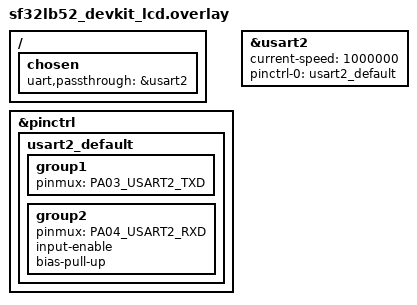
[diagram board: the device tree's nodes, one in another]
/*
 * Copyright (c) 2026 SiFli
 *
 * SPDX-License-Identifier: Apache-2.0
 */

&pinctrl {

    
	usart2_default: usart2_default {
		group1 {
			pinmux = <PA03_USART2_TXD>;
		};

		group2 {
			pinmux = <PA04_USART2_RXD>;
			input-enable;
			bias-pull-up;
		};
	};
};

/ {
	chosen {
		uart,passthrough = &usart2;
	};
};

&usart2 {
	current-speed = <1000000>;
	pinctrl-0 = <&usart2_default>;
	pinctrl-names = "default";
	status = "okay";
};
